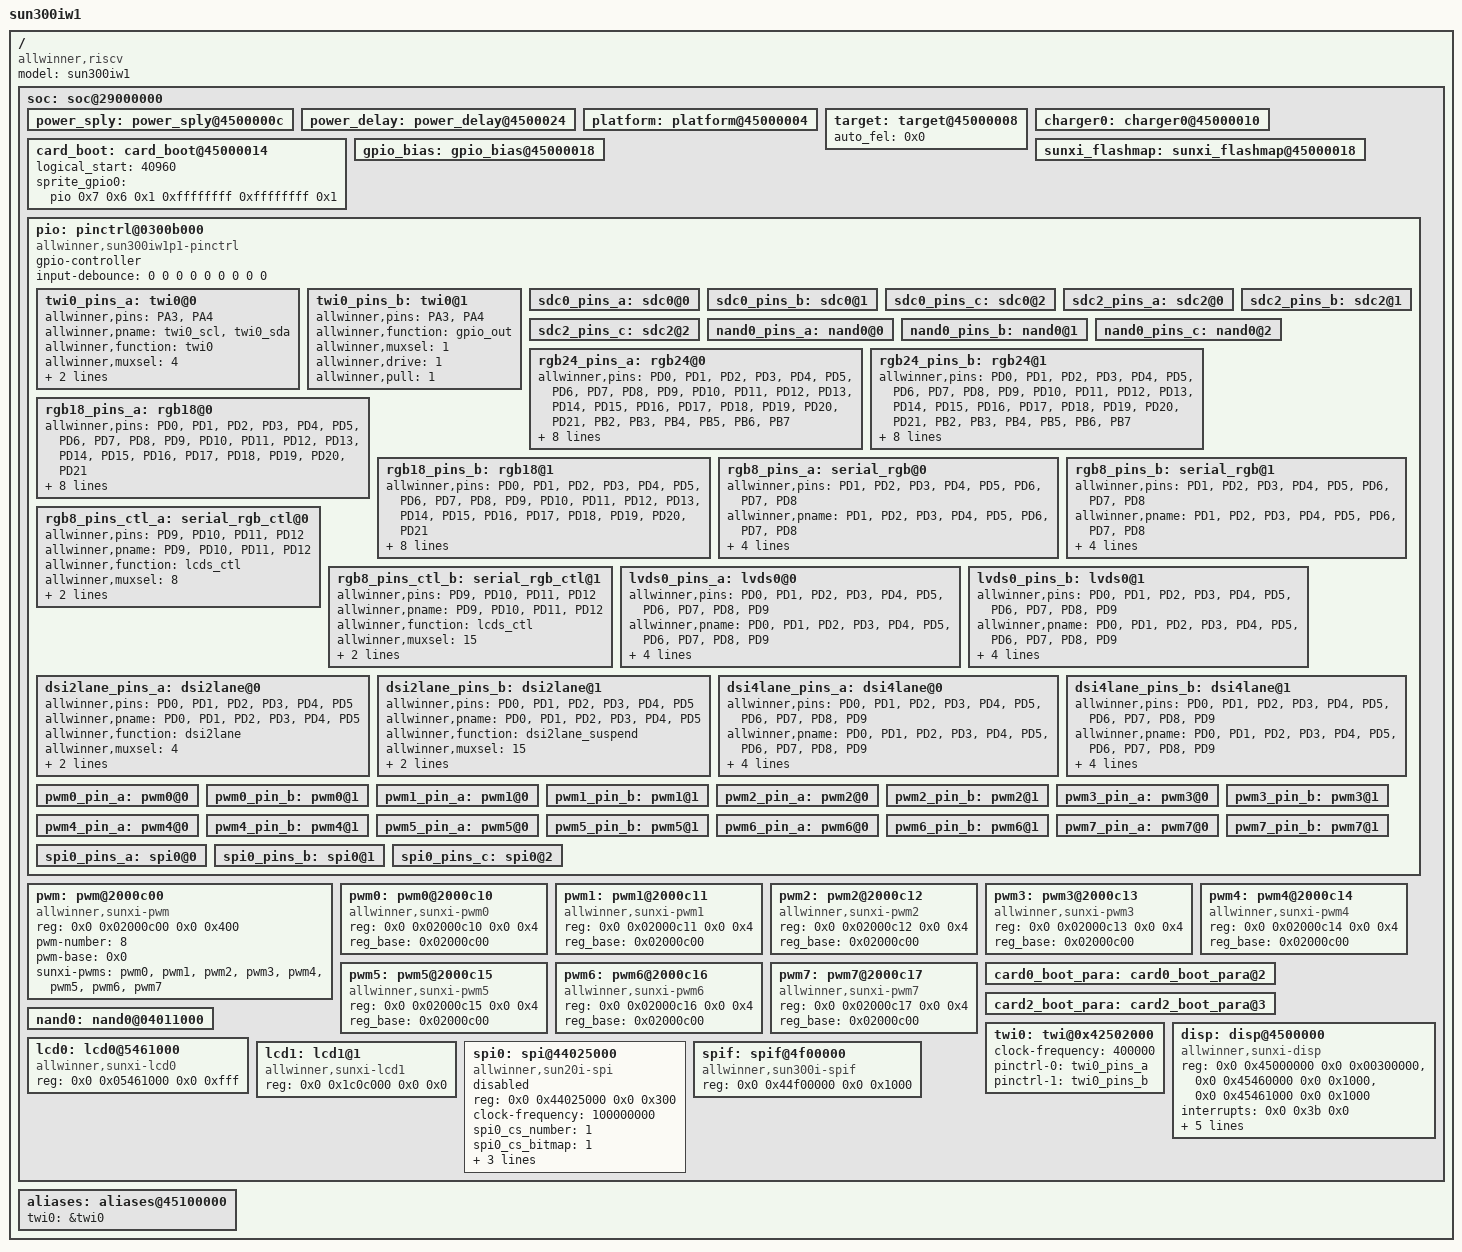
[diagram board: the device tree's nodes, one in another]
/*
 * Allwinner Technology CO., Ltd. sun300iw1p1 platform
 *
 * modify base on juno.dts
 */
/dts-v1/;
#include <dt-bindings/gpio/gpio.h>
#include <dt-bindings/thermal/thermal.h>
#include "sun300iw1p1-clk.dtsi"
/ {
	model = "sun300iw1";
	compatible = "allwinner,riscv", "riscv,sun300iw1p1";
	#address-cells = <2>;
	#size-cells = <2>;
	soc: soc@29000000 {
		#address-cells = <2>;
		#size-cells = <2>;
		power_sply:power_sply@4500000c {
			device_type = "power_sply";

		};

		power_delay:power_delay@4500024 {
			device_type = "power_delay";
		};

		platform:platform@45000004 {
			device_type = "platform";

		};

		target:target@45000008 {
			device_type = "target";
			auto_fel = <0x0>;
		};

		charger0:charger0@45000010 {
			device_type = "charger0";

		};
		card_boot:card_boot@45000014 {
			device_type = "card_boot";
			logical_start   = <40960>;
			/* sprite_gpio0 = <&pio PH 6 1 0xffffffff 0xffffffff 1>; */
			sprite_gpio0 = <&pio 0x7 0x6 0x1 0xffffffff 0xffffffff 0x1>;
		};

		gpio_bias:gpio_bias@45000018 {
			device_type = "gpio_bias";
		};

		sunxi_flashmap:sunxi_flashmap@45000018 {
			device_type = "sunxi_flashmap";
		};

		pio: pinctrl@0300b000 {
			compatible = "allwinner,sun300iw1p1-pinctrl";
			device_type = "pio";
			gpio-controller;
			#size-cells = <0>;
			#gpio-cells = <6>;
			/* takes the debounce time in usec as argument */
			input-debounce = <0 0 0 0 0 0 0 0 0>;

			twi0_pins_a: twi0@0 {
				allwinner,pins = "PA3", "PA4";
				allwinner,pname = "twi0_scl", "twi0_sda";
				allwinner,function = "twi0";
				allwinner,muxsel = <4>;
				allwinner,drive = <1>;
				allwinner,pull = <1>;
			};

			twi0_pins_b: twi0@1 {
				allwinner,pins = "PA3", "PA4";
				allwinner,function = "gpio_out";
				allwinner,muxsel = <1>;
				allwinner,drive = <1>;
				allwinner,pull = <1>;
			};

			sdc0_pins_a: sdc0@0 {
			};

			sdc0_pins_b: sdc0@1 {
			};

			sdc0_pins_c: sdc0@2 {
			};

			sdc2_pins_a: sdc2@0 {
			};

			sdc2_pins_b: sdc2@1 {
			};

			sdc2_pins_c: sdc2@2 {
			};

			nand0_pins_a: nand0@0 {
			};

			nand0_pins_b: nand0@1 {
			};

			nand0_pins_c: nand0@2 {
			};

			rgb24_pins_a: rgb24@0 {
				allwinner,pins = "PD0", "PD1", "PD2", "PD3", "PD4", "PD5", "PD6", "PD7", "PD8", "PD9", \
				"PD10", "PD11", "PD12", "PD13", "PD14", "PD15", "PD16", "PD17", "PD18", "PD19", \
				"PD20", "PD21", "PB2", "PB3", "PB4", "PB5", "PB6", "PB7";
				allwinner,pname = "PD0", "PD1", "PD2", "PD3", "PD4", "PD5", "PD6", "PD7", "PD8", "PD9", \
				"PD10", "PD11", "PD12", "PD13", "PD14", "PD15", "PD16", "PD17", "PD18", "PD19", \
				"PD20", "PD21", "PB2", "PB3", "PB4", "PB5", "PB6", "PB7";
				allwinner,function = "rgb18";
				allwinner,muxsel = <2>;
				allwinner,drive = <3>;
				allwinner,pull = <0>;
			};

			rgb24_pins_b: rgb24@1 {
				allwinner,pins = "PD0", "PD1", "PD2", "PD3", "PD4", "PD5", "PD6", "PD7", "PD8", "PD9", \
				"PD10", "PD11", "PD12", "PD13", "PD14", "PD15", "PD16", "PD17", "PD18", "PD19", \
				"PD20", "PD21", "PB2", "PB3", "PB4", "PB5", "PB6", "PB7";
				allwinner,pname = "PD0", "PD1", "PD2", "PD3", "PD4", "PD5", "PD6", "PD7", "PD8", "PD9", \
				"PD10", "PD11", "PD12", "PD13", "PD14", "PD15", "PD16", "PD17", "PD18", "PD19", \
				"PD20", "PD21", "PB2", "PB3", "PB4", "PB5", "PB6", "PB7";
				allwinner,function = "rgb18_suspend";
				allwinner,muxsel = <15>;
				allwinner,drive = <1>;
				allwinner,pull = <0>;
			};

			rgb18_pins_a: rgb18@0 {
				allwinner,pins = "PD0", "PD1", "PD2", "PD3", "PD4", "PD5", "PD6", "PD7", "PD8", "PD9", \
				"PD10", "PD11", "PD12", "PD13", "PD14", "PD15", "PD16", "PD17", "PD18", "PD19", \
				"PD20", "PD21";
				allwinner,pname = "PD0", "PD1", "PD2", "PD3", "PD4", "PD5", "PD6", "PD7", "PD8", "PD9", \
				"PD10", "PD11", "PD12", "PD13", "PD14", "PD15", "PD16", "PD17", "PD18", "PD19", \
				"PD20", "PD21";
				allwinner,function = "rgb18";
				allwinner,muxsel = <2>;
				allwinner,drive = <3>;
				allwinner,pull = <0>;
			};

			rgb18_pins_b: rgb18@1 {
				allwinner,pins = "PD0", "PD1", "PD2", "PD3", "PD4", "PD5", "PD6", "PD7", "PD8", "PD9", \
				"PD10", "PD11", "PD12", "PD13", "PD14", "PD15", "PD16", "PD17", "PD18", "PD19", \
				"PD20", "PD21";
				allwinner,pname = "PD0", "PD1", "PD2", "PD3", "PD4", "PD5", "PD6", "PD7", "PD8", "PD9", \
				"PD10", "PD11", "PD12", "PD13", "PD14", "PD15", "PD16", "PD17", "PD18", "PD19", \
				"PD20", "PD21";
				allwinner,function = "rgb18_suspend";
				allwinner,muxsel = <15>;
				allwinner,drive = <1>;
				allwinner,pull = <0>;
			};

			rgb8_pins_a: serial_rgb@0 {
				allwinner,pins = "PD1", "PD2", "PD3", "PD4", "PD5", "PD6", "PD7", "PD8";
				allwinner,pname = "PD1", "PD2", "PD3", "PD4", "PD5", "PD6", "PD7", "PD8";
				allwinner,function = "rgb8";
				allwinner,muxsel = <2>;
				allwinner,drive = <2>;
				allwinner,pull = <0>;
			};

			rgb8_pins_b: serial_rgb@1 {
				allwinner,pins = "PD1", "PD2", "PD3", "PD4", "PD5", "PD6", "PD7", "PD8";
				allwinner,pname = "PD1", "PD2", "PD3", "PD4", "PD5", "PD6", "PD7", "PD8";
				allwinner,function = "rgb8_suspend";
				allwinner,muxsel = <15>;
				allwinner,drive = <2>;
				allwinner,pull = <0>;
			};

			rgb8_pins_ctl_a: serial_rgb_ctl@0 {
				allwinner,pins = "PD9", "PD10", "PD11", "PD12";
				allwinner,pname = "PD9", "PD10", "PD11", "PD12";
				allwinner,function = "lcds_ctl";
				allwinner,muxsel = <8>;
				allwinner,drive = <2>;
				allwinner,pull = <0>;
			};

			rgb8_pins_ctl_b: serial_rgb_ctl@1 {
				allwinner,pins = "PD9", "PD10", "PD11", "PD12";
				allwinner,pname = "PD9", "PD10", "PD11", "PD12";
				allwinner,function = "lcds_ctl";
				allwinner,muxsel = <15>;
				allwinner,drive = <2>;
				allwinner,pull = <0>;
			};

			lvds0_pins_a: lvds0@0 {
				allwinner,pins  = "PD0", "PD1", "PD2", "PD3", "PD4", "PD5", "PD6", "PD7", "PD8", "PD9";
				allwinner,pname = "PD0", "PD1", "PD2", "PD3", "PD4", "PD5", "PD6", "PD7", "PD8", "PD9";
				allwinner,function = "lvds0";
				allwinner,muxsel = <3>;
				allwinner,drive = <3>;
				allwinner,pull = <0>;
			};

			lvds0_pins_b: lvds0@1 {
				allwinner,pins  = "PD0", "PD1", "PD2", "PD3", "PD4", "PD5", "PD6", "PD7", "PD8", "PD9";
				allwinner,pname = "PD0", "PD1", "PD2", "PD3", "PD4", "PD5", "PD6", "PD7", "PD8", "PD9";
				allwinner,function = "io_disabled";
				allwinner,muxsel = <15>;
				allwinner,drive = <3>;
				allwinner,pull = <0>;
			};

			dsi2lane_pins_a: dsi2lane@0 {
				allwinner,pins = "PD0", "PD1", "PD2", "PD3", "PD4", "PD5";
				allwinner,pname = "PD0", "PD1", "PD2", "PD3", "PD4", "PD5";
				allwinner,function = "dsi2lane";
				allwinner,muxsel = <4>;
				allwinner,drive = <3>;
				allwinner,pull = <0>;
			};

			dsi2lane_pins_b: dsi2lane@1 {
				allwinner,pins = "PD0", "PD1", "PD2", "PD3", "PD4", "PD5";
				allwinner,pname = "PD0", "PD1", "PD2", "PD3", "PD4", "PD5";
				allwinner,function = "dsi2lane_suspend";
				allwinner,muxsel = <15>;
				allwinner,drive = <1>;
				allwinner,pull = <0>;
			};

			dsi4lane_pins_a: dsi4lane@0 {
				allwinner,pins = "PD0", "PD1", "PD2", "PD3", "PD4", "PD5", "PD6", "PD7", "PD8", "PD9";
				allwinner,pname = "PD0", "PD1", "PD2", "PD3", "PD4", "PD5", "PD6", "PD7", "PD8", "PD9";
				allwinner,function = "dsi4lane";
				allwinner,muxsel = <4>;
				allwinner,drive = <3>;
				allwinner,pull = <0>;
			};

			dsi4lane_pins_b: dsi4lane@1 {
				allwinner,pins = "PD0", "PD1", "PD2", "PD3", "PD4", "PD5", "PD6", "PD7", "PD8", "PD9";
				allwinner,pname = "PD0", "PD1", "PD2", "PD3", "PD4", "PD5", "PD6", "PD7", "PD8", "PD9";
				allwinner,function = "dsi4lane_suspend";
				allwinner,muxsel = <15>;
				allwinner,drive = <1>;
				allwinner,pull = <0>;
			};
			pwm0_pin_a: pwm0@0 {
			};

			pwm0_pin_b: pwm0@1 {
			};

			pwm1_pin_a: pwm1@0 {
			};

			pwm1_pin_b: pwm1@1 {
			};

			pwm2_pin_a: pwm2@0 {
			};

			pwm2_pin_b: pwm2@1 {
			};

			pwm3_pin_a: pwm3@0 {
			};

			pwm3_pin_b: pwm3@1 {
			};

			pwm4_pin_a: pwm4@0 {
			};

			pwm4_pin_b: pwm4@1 {
			};

			pwm5_pin_a: pwm5@0 {
			};

			pwm5_pin_b: pwm5@1 {
			};

			pwm6_pin_a: pwm6@0 {
			};

			pwm6_pin_b: pwm6@1 {
			};

			pwm7_pin_a: pwm7@0 {
			};

			pwm7_pin_b: pwm7@1 {
			};

			spi0_pins_a: spi0@0 {
			};

			spi0_pins_b: spi0@1 {
			};

			spi0_pins_c: spi0@2 {
			};

		};

		pwm: pwm@2000c00 {
			#pwm-cells = <0x3>;
			compatible = "allwinner,sunxi-pwm";
			reg = <0x0 0x02000c00 0x0 0x400>;
			pwm-number = <8>;
			pwm-base = <0x0>;
			sunxi-pwms = <&pwm0>, <&pwm1>, <&pwm2>, <&pwm3>,
				     <&pwm4>, <&pwm5>, <&pwm6>, <&pwm7>;
		};

		pwm0: pwm0@2000c10 {
			compatible = "allwinner,sunxi-pwm0";
			pinctrl-names = "active", "sleep";
			reg = <0x0 0x02000c10 0x0 0x4>;
			reg_base = <0x02000c00>;
		};

		pwm1: pwm1@2000c11 {
			compatible = "allwinner,sunxi-pwm1";
			pinctrl-names = "active", "sleep";
			reg = <0x0 0x02000c11 0x0 0x4>;
			reg_base = <0x02000c00>;
		};

		pwm2: pwm2@2000c12 {
			compatible = "allwinner,sunxi-pwm2";
			pinctrl-names = "active", "sleep";
			reg = <0x0 0x02000c12 0x0 0x4>;
			reg_base = <0x02000c00>;
		};

		pwm3: pwm3@2000c13 {
			compatible = "allwinner,sunxi-pwm3";
			pinctrl-names = "active", "sleep";
			reg = <0x0 0x02000c13 0x0 0x4>;
			reg_base = <0x02000c00>;
		};

		pwm4: pwm4@2000c14 {
			compatible = "allwinner,sunxi-pwm4";
			pinctrl-names = "active", "sleep";
			reg = <0x0 0x02000c14 0x0 0x4>;
			reg_base = <0x02000c00>;
		};

		pwm5: pwm5@2000c15 {
			compatible = "allwinner,sunxi-pwm5";
			pinctrl-names = "active", "sleep";
			reg = <0x0 0x02000c15 0x0 0x4>;
			reg_base = <0x02000c00>;
		};

		pwm6: pwm6@2000c16 {
			compatible = "allwinner,sunxi-pwm6";
			pinctrl-names = "active", "sleep";
			reg = <0x0 0x02000c16 0x0 0x4>;
			reg_base = <0x02000c00>;
		};

		pwm7: pwm7@2000c17 {
			compatible = "allwinner,sunxi-pwm7";
			pinctrl-names = "active", "sleep";
			reg = <0x0 0x02000c17 0x0 0x4>;
			reg_base = <0x02000c00>;
		};

		card0_boot_para:card0_boot_para@2 {
			device_type = "card0_boot_para";
		};

		card2_boot_para:card2_boot_para@3 {
			device_type = "card2_boot_para";
		};

		nand0:nand0@04011000 {
			device_type = "nand0";
		};

		twi0: twi@0x42502000 {
			clock-frequency = <400000>;
			pinctrl-0 = <&twi0_pins_a>;
			pinctrl-1 = <&twi0_pins_b>;
			status = "okay";
		};

		disp: disp@4500000 {
			compatible = "allwinner,sunxi-disp";
			reg = <0x0 0x45000000 0x0 0x00300000>,/* de */
				<0x0 0x45460000 0x0 0x1000>,/* disp sys */
				<0x0 0x45461000 0x0 0x1000>;/* tcon0 */
			interrupts =
				<0x0 0x3b 0x0>; /* tcon0_irq, just to get the id(a27), & -32 */
				/* <&plic0 88 IRQ_TYPE_LEVEL_HIGH>, // de wb irq */
			clocks = <&clk_de>,
				 <&clk_dpss_top0_bus>,
				 <&clk_tcon_lcd>,
				 <&clk_de_hb>,
				 <&clk_disp_ahb>,
				 <&clk_disp_mbus>,
				 <&clk_tcon>;
			boot_disp = <0>;
			fb_base = <0>;
			status = "okay";
		};

		lcd0: lcd0@5461000 {
			#address-cells = <2>;
			#size-cells = <2>;

			compatible = "allwinner,sunxi-lcd0";
			reg = <0x0 0x05461000 0x0 0xfff>;
			pinctrl-names = "active","sleep";
			status = "okay";
		};

		lcd1: lcd1@1 {
			compatible = "allwinner,sunxi-lcd1";
			reg = <0x0 0x1c0c000 0x0 0x0>;  /* Fake registers to avoid dtc compiling warnings */
			pinctrl-names = "active","sleep";
			status = "okay";
		};

		spi0: spi@44025000 {
			#address-cells = <1>;
			#size-cells = <0>;
			compatible = "allwinner,sun20i-spi";
			device_type = "spi0";
			reg = <0x0 0x44025000 0x0 0x300>;
			//interrupts-extended = <&plic0 31 IRQ_TYPE_LEVEL_HIGH>;
			//clocks = <&ccu CLK_PLL_PERIPH0>, <&ccu CLK_SPI0>, <&ccu CLK_BUS_SPI0>;
			//clock-names = "pll", "mod", "bus";
			//resets = <&ccu RST_BUS_SPI0>;
			clock-frequency = <100000000>;
			pinctrl-names = "default", "sleep";
			spi0_cs_number = <1>;
			spi0_cs_bitmap = <1>;
			spi_slave_mode = <0>;
			//dmas = <&dma 22>, <&dma 22>;
			//dma-names = "tx", "rx";
			pinctrl-0 = <&spi0_pins_a &spi0_pins_b>;
			pinctrl-1 = <&spi0_pins_c>;
			status = "disabled";
		};

		spif: spif@4f00000 {
			#address-cells = <1>;
			#size-cells = <0>;
			compatible = "allwinner,sun300i-spif";
			device_type = "spif";
			reg = <0x0 0x44f00000 0x0 0x1000>;
			//interrupts-extended = <&plic0 19 IRQ_TYPE_LEVEL_HIGH>;
			//clocks = <&ccu CLK_PLL_PERIPH0>, <&ccu CLK_SPIF>, <&ccu CLK_BUS_SPIF>;
			//clock-names = "pll", "mod", "bus";
			//resets = <&ccu RST_BUS_SPIF>;
		};
	};

	aliases:aliases@45100000 {
		twi0 = &twi0;
	};

};

#include ".board-uboot.dts"
